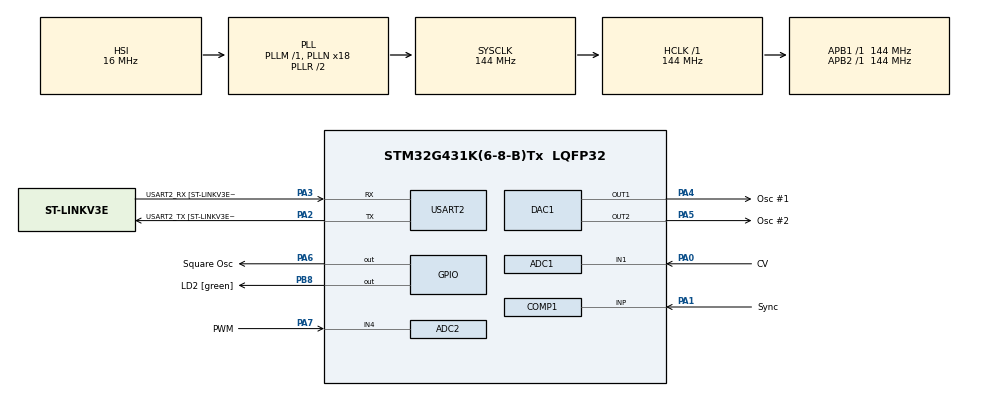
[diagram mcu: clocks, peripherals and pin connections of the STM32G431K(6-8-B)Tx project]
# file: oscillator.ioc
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ADC1.Channel-0\#ChannelRegularConversion=ADC_CHANNEL_1
ADC1.ClockPrescaler=ADC_CLOCK_ASYNC_DIV256
ADC1.ContinuousConvMode=ENABLE
ADC1.DMAContinuousRequests=DISABLE
ADC1.NbrOfConversion=1
ADC1.NbrOfConversionFlag=1
ADC1.OffsetNumber-0\#ChannelRegularConversion=ADC_OFFSET_NONE
ADC1.OversamplingMode=DISABLE
ADC1.Rank-0\#ChannelRegularConversion=1
ADC1.SamplingTime-0\#ChannelRegularConversion=ADC_SAMPLETIME_2CYCLES_5
ADC1.master=1
ADC2.Channel-1\#ChannelRegularConversion=ADC_CHANNEL_4
ADC2.ClockPrescaler=ADC_CLOCK_ASYNC_DIV256
ADC2.ContinuousConvMode=ENABLE
ADC2.NbrOfConversionFlag=1
ADC2.OffsetNumber-1\#ChannelRegularConversion=ADC_OFFSET_NONE
ADC2.Rank-1\#ChannelRegularConversion=1
ADC2.SamplingTime-1\#ChannelRegularConversion=ADC_SAMPLETIME_2CYCLES_5
COMP1.Hysteresis=COMP_HYSTERESIS_HIGH
COMP1.TriggerMode=COMP_TRIGGERMODE_IT_RISING_FALLING
DAC1.DAC_Channel-DAC_OUT2=DAC_CHANNEL_2
Mcu.Family=STM32G4
Mcu.Name=STM32G431K(6-8-B)Tx
Mcu.Package=LQFP32
NVIC.ADC1_2_IRQn=true\:1\:0\:true\:false\:true\:true\:true
NVIC.COMP1_2_3_IRQn=true\:0\:0\:false\:false\:true\:false\:true
NVIC.PriorityGroup=NVIC_PRIORITYGROUP_4
NVIC.TIM1_UP_TIM16_IRQn=true\:0\:0\:false\:false\:true\:true\:true
PA0.GPIO_Label=CV
PA0.Mode=IN1-Single-Ended
PA0.Signal=ADC1_IN1
PA1.GPIO_Label=Sync
PA1.Mode=INP
PA1.Signal=COMP1_INP
PA13.GPIO_Label=T_SWDIO
PA13.Mode=Serial_Wire
PA13.Signal=SYS_JTMS-SWDIO
PA14.GPIO_Label=T_SWCLK
PA14.Mode=Serial_Wire
PA14.Signal=SYS_JTCK-SWCLK
PA2.GPIO_Label=USART2_TX [ST-LINKV3E_VCP_RX]
PA2.Mode=Asynchronous
PA2.Signal=USART2_TX
PA3.GPIO_Label=USART2_RX [ST-LINKV3E_VCP_TX]
PA3.Mode=Asynchronous
PA3.Signal=USART2_RX
PA4.GPIO_Label=Osc \#1
PA4.Signal=COMP_DAC11_group
PA5.GPIO_Label=Osc \#2
PA5.Signal=COMP_DAC12_group
PA6.GPIO_Label=Square Osc
PA6.Signal=GPIO_Output
PA7.GPIO_Label=PWM
PA7.Mode=IN4-Single-Ended
PA7.Signal=ADC2_IN4
PB3.GPIO_Label=T_SWO
PB3.Signal=SYS_JTDO-SWO
PB8-BOOT0.GPIO_Label=LD2 [green]
PB8-BOOT0.Signal=GPIO_Output
ProjectManager.HeapSize=0x200
ProjectManager.StackSize=0x400
ProjectManager.TargetToolchain=STM32CubeIDE
RCC.ADC12Freq_Value=144000000
RCC.AHBFreq_Value=144000000
RCC.APB1Freq_Value=144000000
RCC.APB1TimFreq_Value=144000000
RCC.APB2Freq_Value=144000000
RCC.APB2TimFreq_Value=144000000
RCC.CortexFreq_Value=144000000
RCC.EXTERNAL_CLOCK_VALUE=12288000
RCC.HCLKFreq_Value=144000000
RCC.HSE_VALUE=8000000
RCC.HSI48_VALUE=48000000
RCC.HSI_VALUE=16000000
RCC.LSE_VALUE=32768
RCC.PLLN=18
RCC.SYSCLKFreq_VALUE=144000000
RCC.SYSCLKSource=RCC_SYSCLKSOURCE_PLLCLK
RCC.USBFreq_Value=144000000
RCC.VCOOutputFreq_Value=288000000
SH.COMP_DAC11_group.0=DAC1_OUT1,DAC_OUT1
SH.COMP_DAC12_group.0=DAC1_OUT2,DAC_OUT2
TIM16.PeriodNoDither=2999
TIM16.Prescaler=0
USART2.VirtualMode-Asynchronous=VM_ASYNC
USART2.WordLength=WORDLENGTH_8B
VP_COMP1_VS_VREFINT12.Mode=VREFINT_12
VP_DAC3_VS_DACI1.Mode=DAC_OUT1_Int
VP_SYS_VS_DBSignals.Mode=DisableDeadBatterySignals
VP_TIM16_VS_ClockSourceINT.Mode=Enable_Timer
board=NUCLEO-G431KB

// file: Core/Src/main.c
/* USER CODE BEGIN Header */
/**
  ******************************************************************************
  * @file           : main.c
  * @brief          : Main program body
  ******************************************************************************
  * @attention
  *
  * <h2><center>&copy; Copyright (c) 2021 STMicroelectronics.
  * All rights reserved.</center></h2>
  *
  * This software component is licensed by ST under BSD 3-Clause license,
  * the "License"; You may not use this file except in compliance with the
  * License. You may obtain a copy of the License at:
  *                        opensource.org/licenses/BSD-3-Clause
  *
  ******************************************************************************
  */
/* USER CODE END Header */
#include "main.h"

/* USER CODE BEGIN PD */
// #define ADC_INPUT_MAX 4096
// #define ADC_BUF_LEN 1024
/* USER CODE END PD */

ADC_HandleTypeDef hadc1;
ADC_HandleTypeDef hadc2;

COMP_HandleTypeDef hcomp1;

DAC_HandleTypeDef hdac1;
DAC_HandleTypeDef hdac3;

TIM_HandleTypeDef htim16;

UART_HandleTypeDef huart2;

/* USER CODE BEGIN PV */

// volatile uint8_t quantize_notes = 0;
// uint16_t adc_buf[ADC_BUF_LEN];

/* USER CODE END PV */

void SystemClock_Config(void);
static void MX_GPIO_Init(void);
static void MX_USART2_UART_Init(void);
static void MX_ADC1_Init(void);
static void MX_DAC1_Init(void);
static void MX_TIM16_Init(void);
static void MX_COMP1_Init(void);
static void MX_ADC2_Init(void);
static void MX_DAC3_Init(void);

int main(void)
{

  /* MCU Configuration--------------------------------------------------------*/

  /* Reset of all peripherals, Initializes the Flash interface and the Systick. */
  HAL_Init();

  /* Configure the system clock */
  SystemClock_Config();

  /* Initialize all configured peripherals */
  MX_GPIO_Init();
  MX_USART2_UART_Init();
  MX_ADC1_Init();
  MX_DAC1_Init();
  MX_TIM16_Init();
  MX_COMP1_Init();
  MX_ADC2_Init();
  MX_DAC3_Init();
  /* USER CODE BEGIN 2 */
  HAL_ADCEx_Calibration_Start(&hadc1, ADC_SINGLE_ENDED);
  HAL_ADC_Start_IT(&hadc1);

  HAL_ADCEx_Calibration_Start(&hadc2, ADC_SINGLE_ENDED);
  HAL_ADC_Start_IT(&hadc2);

  HAL_COMP_Start(&hcomp1);

  HAL_TIM_Base_Start_IT(&htim16);
  HAL_DAC_Start(&hdac1, DAC_CHANNEL_1);
  HAL_DAC_Start(&hdac1, DAC_CHANNEL_2);

  /* USER CODE END 2 */

  /* Infinite loop */
  while (1)
  {

  }
}

void SystemClock_Config(void)
{
  RCC_OscInitTypeDef RCC_OscInitStruct = {0};
  RCC_ClkInitTypeDef RCC_ClkInitStruct = {0};
  RCC_PeriphCLKInitTypeDef PeriphClkInit = {0};

  /** Configure the main internal regulator output voltage
  */
  HAL_PWREx_ControlVoltageScaling(PWR_REGULATOR_VOLTAGE_SCALE1);
  /** Initializes the RCC Oscillators according to the specified parameters
  * in the RCC_OscInitTypeDef structure.
  */
  RCC_OscInitStruct.OscillatorType = RCC_OSCILLATORTYPE_HSI;
  RCC_OscInitStruct.HSIState = RCC_HSI_ON;
  RCC_OscInitStruct.HSICalibrationValue = RCC_HSICALIBRATION_DEFAULT;
  RCC_OscInitStruct.PLL.PLLState = RCC_PLL_ON;
  RCC_OscInitStruct.PLL.PLLSource = RCC_PLLSOURCE_HSI;
  RCC_OscInitStruct.PLL.PLLM = RCC_PLLM_DIV1;
  RCC_OscInitStruct.PLL.PLLN = 18;
  RCC_OscInitStruct.PLL.PLLP = RCC_PLLP_DIV2;
  RCC_OscInitStruct.PLL.PLLQ = RCC_PLLQ_DIV2;
  RCC_OscInitStruct.PLL.PLLR = RCC_PLLR_DIV2;
  if (HAL_RCC_OscConfig(&RCC_OscInitStruct) != HAL_OK)
  {
    Error_Handler();
  }
  /** Initializes the CPU, AHB and APB buses clocks
  */
  RCC_ClkInitStruct.ClockType = RCC_CLOCKTYPE_HCLK|RCC_CLOCKTYPE_SYSCLK
                              |RCC_CLOCKTYPE_PCLK1|RCC_CLOCKTYPE_PCLK2;
  RCC_ClkInitStruct.SYSCLKSource = RCC_SYSCLKSOURCE_PLLCLK;
  RCC_ClkInitStruct.AHBCLKDivider = RCC_SYSCLK_DIV1;
  RCC_ClkInitStruct.APB1CLKDivider = RCC_HCLK_DIV1;
  RCC_ClkInitStruct.APB2CLKDivider = RCC_HCLK_DIV1;

  if (HAL_RCC_ClockConfig(&RCC_ClkInitStruct, FLASH_LATENCY_4) != HAL_OK)
  {
    Error_Handler();
  }
  /** Initializes the peripherals clocks
  */
  PeriphClkInit.PeriphClockSelection = RCC_PERIPHCLK_USART2|RCC_PERIPHCLK_ADC12;
  PeriphClkInit.Usart2ClockSelection = RCC_USART2CLKSOURCE_PCLK1;
  PeriphClkInit.Adc12ClockSelection = RCC_ADC12CLKSOURCE_SYSCLK;
  if (HAL_RCCEx_PeriphCLKConfig(&PeriphClkInit) != HAL_OK)
  {
    Error_Handler();
  }
}

static void MX_ADC1_Init(void)
{

  ADC_MultiModeTypeDef multimode = {0};
  ADC_ChannelConfTypeDef sConfig = {0};

  /** Common config
  */
  hadc1.Instance = ADC1;
  hadc1.Init.ClockPrescaler = ADC_CLOCK_ASYNC_DIV256;
  hadc1.Init.Resolution = ADC_RESOLUTION_12B;
  hadc1.Init.DataAlign = ADC_DATAALIGN_RIGHT;
  hadc1.Init.GainCompensation = 0;
  hadc1.Init.ScanConvMode = ADC_SCAN_DISABLE;
  hadc1.Init.EOCSelection = ADC_EOC_SINGLE_CONV;
  hadc1.Init.LowPowerAutoWait = DISABLE;
  hadc1.Init.ContinuousConvMode = ENABLE;
  hadc1.Init.NbrOfConversion = 1;
  hadc1.Init.DiscontinuousConvMode = DISABLE;
  hadc1.Init.ExternalTrigConv = ADC_SOFTWARE_START;
  hadc1.Init.ExternalTrigConvEdge = ADC_EXTERNALTRIGCONVEDGE_NONE;
  hadc1.Init.DMAContinuousRequests = DISABLE;
  hadc1.Init.Overrun = ADC_OVR_DATA_PRESERVED;
  hadc1.Init.OversamplingMode = DISABLE;
  if (HAL_ADC_Init(&hadc1) != HAL_OK)
  {
    Error_Handler();
  }
  /** Configure the ADC multi-mode
  */
  multimode.Mode = ADC_MODE_INDEPENDENT;
  if (HAL_ADCEx_MultiModeConfigChannel(&hadc1, &multimode) != HAL_OK)
  {
    Error_Handler();
  }
  /** Configure Regular Channel
  */
  sConfig.Channel = ADC_CHANNEL_1;
  sConfig.Rank = ADC_REGULAR_RANK_1;
  sConfig.SamplingTime = ADC_SAMPLETIME_2CYCLES_5;
  sConfig.SingleDiff = ADC_SINGLE_ENDED;
  sConfig.OffsetNumber = ADC_OFFSET_NONE;
  sConfig.Offset = 0;
  if (HAL_ADC_ConfigChannel(&hadc1, &sConfig) != HAL_OK)
  {
    Error_Handler();
  }

}

static void MX_ADC2_Init(void)
{

  ADC_ChannelConfTypeDef sConfig = {0};

  /** Common config
  */
  hadc2.Instance = ADC2;
  hadc2.Init.ClockPrescaler = ADC_CLOCK_ASYNC_DIV256;
  hadc2.Init.Resolution = ADC_RESOLUTION_12B;
  hadc2.Init.DataAlign = ADC_DATAALIGN_RIGHT;
  hadc2.Init.GainCompensation = 0;
  hadc2.Init.ScanConvMode = ADC_SCAN_DISABLE;
  hadc2.Init.EOCSelection = ADC_EOC_SINGLE_CONV;
  hadc2.Init.LowPowerAutoWait = DISABLE;
  hadc2.Init.ContinuousConvMode = ENABLE;
  hadc2.Init.NbrOfConversion = 1;
  hadc2.Init.DiscontinuousConvMode = DISABLE;
  hadc2.Init.ExternalTrigConv = ADC_SOFTWARE_START;
  hadc2.Init.ExternalTrigConvEdge = ADC_EXTERNALTRIGCONVEDGE_NONE;
  hadc2.Init.DMAContinuousRequests = DISABLE;
  hadc2.Init.Overrun = ADC_OVR_DATA_PRESERVED;
  hadc2.Init.OversamplingMode = DISABLE;
  if (HAL_ADC_Init(&hadc2) != HAL_OK)
  {
    Error_Handler();
  }
  /** Configure Regular Channel
  */
  sConfig.Channel = ADC_CHANNEL_4;
  sConfig.Rank = ADC_REGULAR_RANK_1;
  sConfig.SamplingTime = ADC_SAMPLETIME_2CYCLES_5;
  sConfig.SingleDiff = ADC_SINGLE_ENDED;
  sConfig.OffsetNumber = ADC_OFFSET_NONE;
  sConfig.Offset = 0;
  if (HAL_ADC_ConfigChannel(&hadc2, &sConfig) != HAL_OK)
  {
    Error_Handler();
  }

}

static void MX_COMP1_Init(void)
{

  hcomp1.Instance = COMP1;
  hcomp1.Init.InputPlus = COMP_INPUT_PLUS_IO1;
  hcomp1.Init.InputMinus = COMP_INPUT_MINUS_1_2VREFINT;
  hcomp1.Init.OutputPol = COMP_OUTPUTPOL_NONINVERTED;
  hcomp1.Init.Hysteresis = COMP_HYSTERESIS_HIGH;
  hcomp1.Init.BlankingSrce = COMP_BLANKINGSRC_NONE;
  hcomp1.Init.TriggerMode = COMP_TRIGGERMODE_IT_RISING_FALLING;
  if (HAL_COMP_Init(&hcomp1) != HAL_OK)
  {
    Error_Handler();
  }

}

static void MX_DAC1_Init(void)
{

  DAC_ChannelConfTypeDef sConfig = {0};

  /** DAC Initialization
  */
  hdac1.Instance = DAC1;
  if (HAL_DAC_Init(&hdac1) != HAL_OK)
  {
    Error_Handler();
  }
  /** DAC channel OUT1 config
  */
  sConfig.DAC_HighFrequency = DAC_HIGH_FREQUENCY_INTERFACE_MODE_AUTOMATIC;
  sConfig.DAC_DMADoubleDataMode = DISABLE;
  sConfig.DAC_SignedFormat = DISABLE;
  sConfig.DAC_SampleAndHold = DAC_SAMPLEANDHOLD_DISABLE;
  sConfig.DAC_Trigger = DAC_TRIGGER_NONE;
  sConfig.DAC_Trigger2 = DAC_TRIGGER_NONE;
  sConfig.DAC_OutputBuffer = DAC_OUTPUTBUFFER_ENABLE;
  sConfig.DAC_ConnectOnChipPeripheral = DAC_CHIPCONNECT_EXTERNAL;
  sConfig.DAC_UserTrimming = DAC_TRIMMING_FACTORY;
  if (HAL_DAC_ConfigChannel(&hdac1, &sConfig, DAC_CHANNEL_1) != HAL_OK)
  {
    Error_Handler();
  }
  /** DAC channel OUT2 config
  */
  if (HAL_DAC_ConfigChannel(&hdac1, &sConfig, DAC_CHANNEL_2) != HAL_OK)
  {
    Error_Handler();
  }

}

static void MX_DAC3_Init(void)
{

  DAC_ChannelConfTypeDef sConfig = {0};

  /** DAC Initialization
  */
  hdac3.Instance = DAC3;
  if (HAL_DAC_Init(&hdac3) != HAL_OK)
  {
    Error_Handler();
  }
  /** DAC channel OUT1 config
  */
  sConfig.DAC_HighFrequency = DAC_HIGH_FREQUENCY_INTERFACE_MODE_AUTOMATIC;
  sConfig.DAC_DMADoubleDataMode = DISABLE;
  sConfig.DAC_SignedFormat = DISABLE;
  sConfig.DAC_SampleAndHold = DAC_SAMPLEANDHOLD_DISABLE;
  sConfig.DAC_Trigger = DAC_TRIGGER_NONE;
  sConfig.DAC_Trigger2 = DAC_TRIGGER_NONE;
  sConfig.DAC_OutputBuffer = DAC_OUTPUTBUFFER_DISABLE;
  sConfig.DAC_ConnectOnChipPeripheral = DAC_CHIPCONNECT_INTERNAL;
  sConfig.DAC_UserTrimming = DAC_TRIMMING_FACTORY;
  if (HAL_DAC_ConfigChannel(&hdac3, &sConfig, DAC_CHANNEL_1) != HAL_OK)
  {
    Error_Handler();
  }

}

static void MX_TIM16_Init(void)
{

  htim16.Instance = TIM16;
  htim16.Init.Prescaler = 0;
  htim16.Init.CounterMode = TIM_COUNTERMODE_UP;
  htim16.Init.Period = 2999;
  htim16.Init.ClockDivision = TIM_CLOCKDIVISION_DIV1;
  htim16.Init.RepetitionCounter = 0;
  htim16.Init.AutoReloadPreload = TIM_AUTORELOAD_PRELOAD_DISABLE;
  if (HAL_TIM_Base_Init(&htim16) != HAL_OK)
  {
    Error_Handler();
  }

}

static void MX_USART2_UART_Init(void)
{

  huart2.Instance = USART2;
  huart2.Init.BaudRate = 115200;
  huart2.Init.WordLength = UART_WORDLENGTH_8B;
  huart2.Init.StopBits = UART_STOPBITS_1;
  huart2.Init.Parity = UART_PARITY_NONE;
  huart2.Init.Mode = UART_MODE_TX_RX;
  huart2.Init.HwFlowCtl = UART_HWCONTROL_NONE;
  huart2.Init.OverSampling = UART_OVERSAMPLING_16;
  huart2.Init.OneBitSampling = UART_ONE_BIT_SAMPLE_DISABLE;
  huart2.Init.ClockPrescaler = UART_PRESCALER_DIV1;
  huart2.AdvancedInit.AdvFeatureInit = UART_ADVFEATURE_NO_INIT;
  if (HAL_UART_Init(&huart2) != HAL_OK)
  {
    Error_Handler();
  }
  if (HAL_UARTEx_SetTxFifoThreshold(&huart2, UART_TXFIFO_THRESHOLD_1_8) != HAL_OK)
  {
    Error_Handler();
  }
  if (HAL_UARTEx_SetRxFifoThreshold(&huart2, UART_RXFIFO_THRESHOLD_1_8) != HAL_OK)
  {
    Error_Handler();
  }
  if (HAL_UARTEx_DisableFifoMode(&huart2) != HAL_OK)
  {
    Error_Handler();
  }

}

static void MX_GPIO_Init(void)
{
  GPIO_InitTypeDef GPIO_InitStruct = {0};

  /* GPIO Ports Clock Enable */
  __HAL_RCC_GPIOA_CLK_ENABLE();
  __HAL_RCC_GPIOB_CLK_ENABLE();

  /*Configure GPIO pin Output Level */
  HAL_GPIO_WritePin(Square_Osc_GPIO_Port, Square_Osc_Pin, GPIO_PIN_RESET);

  /*Configure GPIO pin Output Level */
  HAL_GPIO_WritePin(LD2_GPIO_Port, LD2_Pin, GPIO_PIN_RESET);

  /*Configure GPIO pin : Square_Osc_Pin */
  GPIO_InitStruct.Pin = Square_Osc_Pin;
  GPIO_InitStruct.Mode = GPIO_MODE_OUTPUT_PP;
  GPIO_InitStruct.Pull = GPIO_NOPULL;
  GPIO_InitStruct.Speed = GPIO_SPEED_FREQ_LOW;
  HAL_GPIO_Init(Square_Osc_GPIO_Port, &GPIO_InitStruct);

  /*Configure GPIO pin : LD2_Pin */
  GPIO_InitStruct.Pin = LD2_Pin;
  GPIO_InitStruct.Mode = GPIO_MODE_OUTPUT_PP;
  GPIO_InitStruct.Pull = GPIO_NOPULL;
  GPIO_InitStruct.Speed = GPIO_SPEED_FREQ_LOW;
  HAL_GPIO_Init(LD2_GPIO_Port, &GPIO_InitStruct);

}

void Error_Handler(void)
{
  __disable_irq();
  while (1)
  {
  }
}

/************************ (C) COPYRIGHT STMicroelectronics *****END OF FILE****/
